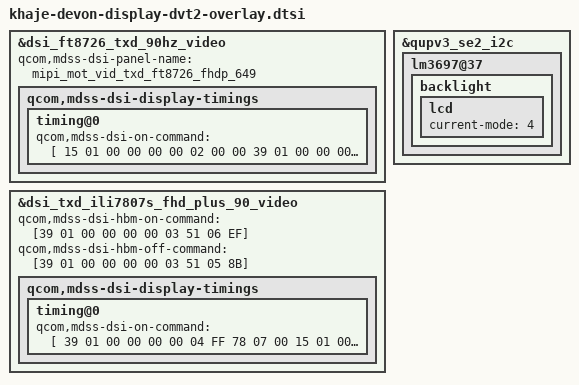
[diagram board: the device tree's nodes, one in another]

&dsi_ft8726_txd_90hz_video {
	qcom,mdss-dsi-panel-name = "mipi_mot_vid_txd_ft8726_fhdp_649";

	qcom,mdss-dsi-display-timings {
		timing@0 {
			qcom,mdss-dsi-on-command = [
				15 01 00 00 00 00 02 00 00
				39 01 00 00 00 00 04 FF 87 20 01
				15 01 00 00 00 00 02 00 80
				39 01 00 00 00 00 03 FF 87 20
				15 01 00 00 00 00 02 00 D2
				15 01 00 00 00 00 02 C0 01
				15 01 00 00 00 00 02 00 F1
				15 01 00 00 00 00 02 CF 5A
				15 01 00 00 00 00 02 00 F6
				15 01 00 00 00 00 02 CF 5A
				15 01 00 00 00 00 02 00 B0
				39 01 00 00 00 00 05 CF 00 00 9B 9F
				15 01 00 00 00 00 02 00 B5
				39 01 00 00 00 00 05 CF 04 04 FB FF
				15 01 00 00 00 00 02 00 B7
				39 01 00 00 00 00 03 CE 1B 09
				15 01 00 00 00 00 02 00 80
				39 01 00 00 00 00 09 C2 83 01 03 82 82 01 03 82
				15 01 00 00 00 00 02 00 D0
				39 01 00 00 00 00 11 C3 35 02 00 00 35 02 00 00 35 02 00 00 35 02 00 00
				15 01 00 00 00 00 02 00 86
				39 01 00 00 00 00 07 C0 01 02 00 01 12 05
				15 01 00 00 00 00 02 00 96
				39 01 00 00 00 00 07 C0 01 02 00 01 12 05
				15 01 00 00 00 00 02 00 A6
				39 01 00 00 00 00 07 C0 01 02 00 01 1B 09
				15 01 00 00 00 00 02 00 A3
				39 01 00 00 00 00 07 CE 01 02 00 01 12 05
				15 01 00 00 00 00 02 00 B3
				39 01 00 00 00 00 07 CE 01 02 00 01 12 05

				15 01 00 00 00 00 02 00 00
				39 01 00 00 00 00 04 FF FF FF FF
				39 00 00 00 00 00 03 51 CC 0C
				15 00 00 00 00 00 02 53 2C
				15 00 00 00 00 00 02 55 01
				15 01 00 00 64 00 02 11 00
				15 01 00 00 0A 00 02 29 00
			];
		};
	};
};

&dsi_txd_ili7807s_fhd_plus_90_video {
	qcom,mdss-dsi-hbm-on-command = [39 01 00 00 00 00 03 51 06 EF];
	qcom,mdss-dsi-hbm-off-command = [39 01 00 00 00 00 03 51 05 8B];

	qcom,mdss-dsi-display-timings {
		timing@0 {
			qcom,mdss-dsi-on-command = [
				39 01 00 00 00 00 04 FF 78 07 00
				15 01 00 00 50 00 02 11 00
				39 01 00 00 00 00 04 FF 78 07 06
				15 01 00 00 00 00 02 3E E3
				15 01 00 00 00 00 02 80	00
				15 01 00 00 00 00 02 4E 64
				15 01 00 00 00 00 02 4D 81
				15 01 00 00 00 00 02 C7 05
				15 01 00 00 00 00 02 48 09
				39 01 00 00 00 00 04 FF	78 07 02
				15 01 00 00 00 00 02 1B	01
				39 01 00 00 00 00 04 FF	78 07 00
				39 01 00 00 00 00 03 51 05 8B
				15 01 00 00 00 00 02 53 2C
				15 01 00 00 00 00 02 55 01
				15 01 00 00 0A 00 02 29 00];
		};
	};
};

&qupv3_se2_i2c {
        status = "ok";
        lm3697@37 {
		backlight {
			lcd {
				current-mode = <4>;	/*4: 23.4mA*/
			};
		};
	};
};

